# regs register map
Registers are 32-bit, access not given, no defined reset value unless marked. A register's access mark holds for its fields unless they carry their own. Addresses are absolute; registers are grouped by the start of their names; [hi:lo] are bit positions; {n}, {i} and the like mark numbered series; 'fields as' and 'values as' point back to an identical list.

## INT
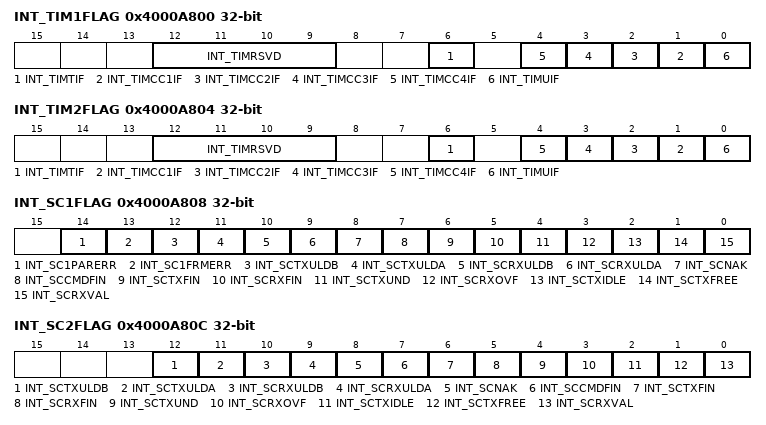
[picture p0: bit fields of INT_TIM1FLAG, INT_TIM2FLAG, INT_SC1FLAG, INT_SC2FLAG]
0x4000A800 INT_TIM1FLAG
  [12:9] INT_TIMRSVD, [6] INT_TIMTIF, [n] INT_TIMCC{n}IF (n=1..4), [0] INT_TIMUIF
0x4000A804 INT_TIM2FLAG
  fields as INT_TIM1FLAG
0x4000A808 INT_SC1FLAG
  [14] INT_SC1PARERR, [13] INT_SC1FRMERR, [12] INT_SCTXULDB, [11] INT_SCTXULDA, [10] INT_SCRXULDB, [9] INT_SCRXULDA, [8] INT_SCNAK, [7] INT_SCCMDFIN, [6] INT_SCTXFIN, [5] INT_SCRXFIN, [4] INT_SCTXUND, [3] INT_SCRXOVF, [2] INT_SCTXIDLE, [1] INT_SCTXFREE, [0] INT_SCRXVAL
0x4000A80C INT_SC2FLAG
  [12] INT_SCTXULDB, [11] INT_SCTXULDA, [10] INT_SCRXULDB, [9] INT_SCRXULDA, [8] INT_SCNAK, [7] INT_SCCMDFIN, [6] INT_SCTXFIN, [5] INT_SCRXFIN, [4] INT_SCTXUND, [3] INT_SCRXOVF, [2] INT_SCTXIDLE, [1] INT_SCTXFREE, [0] INT_SCRXVAL
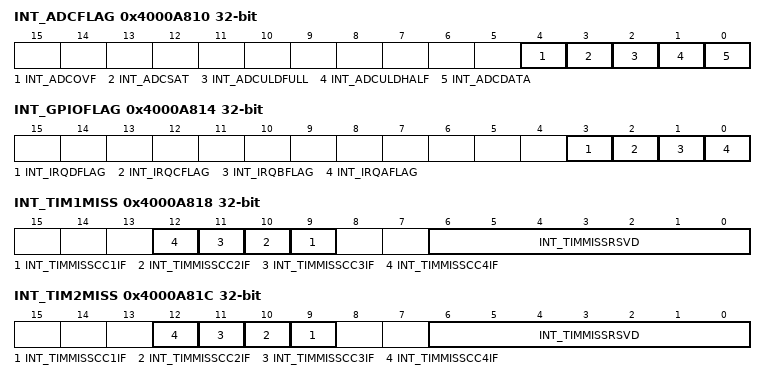
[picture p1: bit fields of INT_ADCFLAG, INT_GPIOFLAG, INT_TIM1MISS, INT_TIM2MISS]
0x4000A810 INT_ADCFLAG
  [4] INT_ADCOVF, [3] INT_ADCSAT, [2] INT_ADCULDFULL, [1] INT_ADCULDHALF, [0] INT_ADCDATA
0x4000A814 INT_GPIOFLAG
  [3] INT_IRQDFLAG, [2] INT_IRQCFLAG, [1] INT_IRQBFLAG, [0] INT_IRQAFLAG
0x4000A818 INT_TIM1MISS
  [n+8] INT_TIMMISSCC{n}IF (n=1..4), [6:0] INT_TIMMISSRSVD
0x4000A81C INT_TIM2MISS
  [n+8] INT_TIMMISSCC{n}IF (n=1..4), [6:0] INT_TIMMISSRSVD
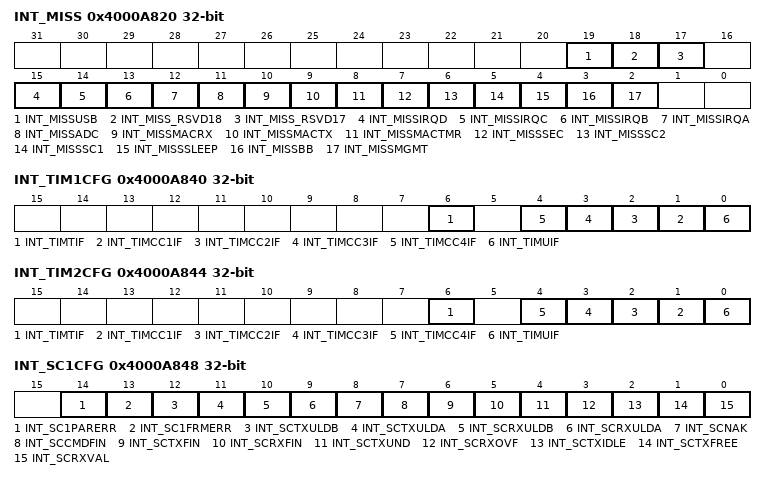
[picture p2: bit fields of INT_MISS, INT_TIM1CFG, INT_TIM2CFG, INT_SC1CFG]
0x4000A820 INT_MISS
  [19] INT_MISSUSB, [18] INT_MISS_RSVD18, [17] INT_MISS_RSVD17, [15] INT_MISSIRQD, [14] INT_MISSIRQC, [13] INT_MISSIRQB, [12] INT_MISSIRQA, [11] INT_MISSADC, [10] INT_MISSMACRX, [9] INT_MISSMACTX, [8] INT_MISSMACTMR, [7] INT_MISSSEC, [6] INT_MISSSC2, [5] INT_MISSSC1, [4] INT_MISSSLEEP, [3] INT_MISSBB, [2] INT_MISSMGMT
0x4000A840 INT_TIM1CFG
  [6] INT_TIMTIF, [n] INT_TIMCC{n}IF (n=1..4), [0] INT_TIMUIF
0x4000A844 INT_TIM2CFG
  [6] INT_TIMTIF, [n] INT_TIMCC{n}IF (n=1..4), [0] INT_TIMUIF
0x4000A848 INT_SC1CFG
  fields as INT_SC1FLAG
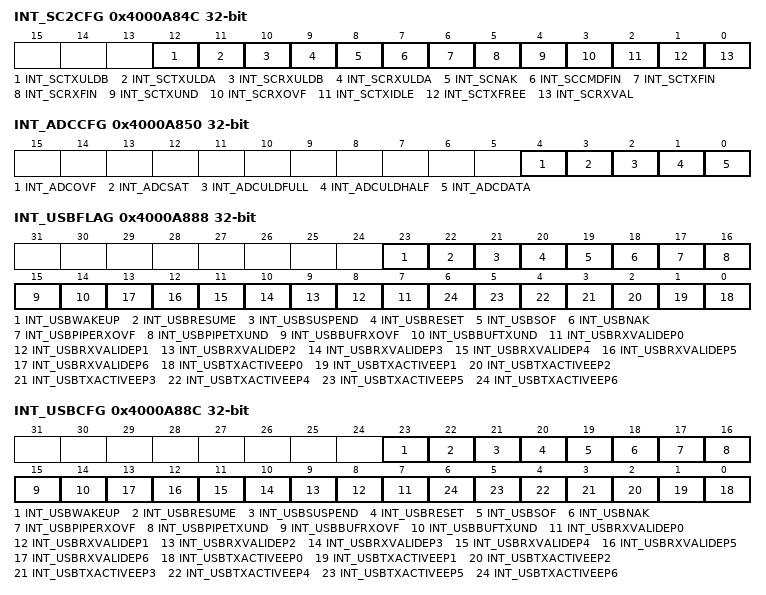
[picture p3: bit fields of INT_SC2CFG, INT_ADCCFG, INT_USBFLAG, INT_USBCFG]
0x4000A84C INT_SC2CFG
  fields as INT_SC2FLAG
0x4000A850 INT_ADCCFG
  fields as INT_ADCFLAG
0x4000A888 INT_USBFLAG
  [23] INT_USBWAKEUP, [22] INT_USBRESUME, [21] INT_USBSUSPEND, [20] INT_USBRESET, [19] INT_USBSOF, [18] INT_USBNAK, [17] INT_USBPIPERXOVF, [16] INT_USBPIPETXUND, [15] INT_USBBUFRXOVF, [14] INT_USBBUFTXUND, [n+7] INT_USBRXVALIDEP{n} (n=0..6), [n] INT_USBTXACTIVEEP{n} (n=0..6)
0x4000A88C INT_USBCFG
  fields as INT_USBFLAG
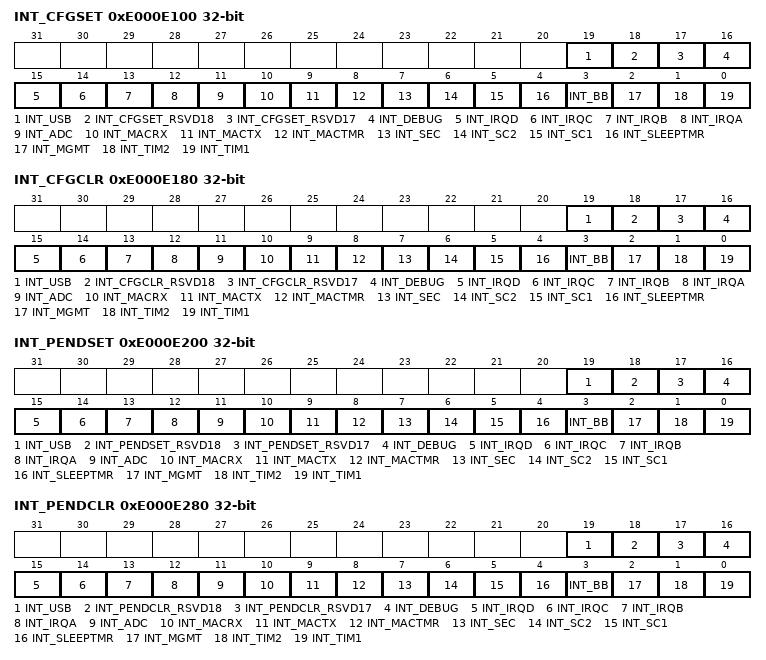
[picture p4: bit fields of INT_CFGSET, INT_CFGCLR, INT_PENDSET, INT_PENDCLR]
0xE000E100 INT_CFGSET
  [19] INT_USB, [18] INT_CFGSET_RSVD18, [17] INT_CFGSET_RSVD17, [16] INT_DEBUG, [15] INT_IRQD, [14] INT_IRQC, [13] INT_IRQB, [12] INT_IRQA, [11] INT_ADC, [10] INT_MACRX, [9] INT_MACTX, [8] INT_MACTMR, [7] INT_SEC, [6] INT_SC2, [5] INT_SC1, [4] INT_SLEEPTMR, [3] INT_BB, [2] INT_MGMT, [1] INT_TIM2, [0] INT_TIM1
0xE000E180 INT_CFGCLR
  [19] INT_USB, [18] INT_CFGCLR_RSVD18, [17] INT_CFGCLR_RSVD17, [16] INT_DEBUG, [15] INT_IRQD, [14] INT_IRQC, [13] INT_IRQB, [12] INT_IRQA, [11] INT_ADC, [10] INT_MACRX, [9] INT_MACTX, [8] INT_MACTMR, [7] INT_SEC, [6] INT_SC2, [5] INT_SC1, [4] INT_SLEEPTMR, [3] INT_BB, [2] INT_MGMT, [1] INT_TIM2, [0] INT_TIM1
0xE000E200 INT_PENDSET
  [19] INT_USB, [18] INT_PENDSET_RSVD18, [17] INT_PENDSET_RSVD17, [16] INT_DEBUG, [15] INT_IRQD, [14] INT_IRQC, [13] INT_IRQB, [12] INT_IRQA, [11] INT_ADC, [10] INT_MACRX, [9] INT_MACTX, [8] INT_MACTMR, [7] INT_SEC, [6] INT_SC2, [5] INT_SC1, [4] INT_SLEEPTMR, [3] INT_BB, [2] INT_MGMT, [1] INT_TIM2, [0] INT_TIM1
0xE000E280 INT_PENDCLR
  [19] INT_USB, [18] INT_PENDCLR_RSVD18, [17] INT_PENDCLR_RSVD17, [16] INT_DEBUG, [15] INT_IRQD, [14] INT_IRQC, [13] INT_IRQB, [12] INT_IRQA, [11] INT_ADC, [10] INT_MACRX, [9] INT_MACTX, [8] INT_MACTMR, [7] INT_SEC, [6] INT_SC2, [5] INT_SC1, [4] INT_SLEEPTMR, [3] INT_BB, [2] INT_MGMT, [1] INT_TIM2, [0] INT_TIM1
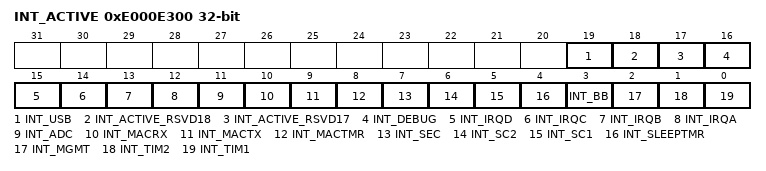
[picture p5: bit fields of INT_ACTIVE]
0xE000E300 INT_ACTIVE
  [19] INT_USB, [18] INT_ACTIVE_RSVD18, [17] INT_ACTIVE_RSVD17, [16] INT_DEBUG, [15] INT_IRQD, [14] INT_IRQC, [13] INT_IRQB, [12] INT_IRQA, [11] INT_ADC, [10] INT_MACRX, [9] INT_MACTX, [8] INT_MACTMR, [7] INT_SEC, [6] INT_SC2, [5] INT_SC1, [4] INT_SLEEPTMR, [3] INT_BB, [2] INT_MGMT, [1] INT_TIM2, [0] INT_TIM1

## Notices in the file
Copyright 2015 Silicon Laboratories, Inc.
